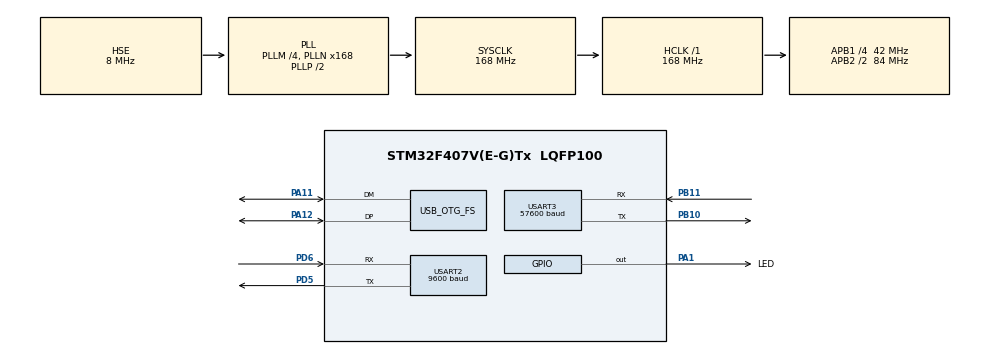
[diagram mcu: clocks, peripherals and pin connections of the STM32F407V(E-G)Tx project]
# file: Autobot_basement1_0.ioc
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Dma.Request0=USART2_RX
Dma.Request1=USART2_TX
Dma.Request2=USART3_RX
Dma.Request3=USART3_TX
Dma.USART2_RX.0.Direction=DMA_PERIPH_TO_MEMORY
Dma.USART2_RX.0.FIFOMode=DMA_FIFOMODE_DISABLE
Dma.USART2_RX.0.Instance=DMA1_Stream5
Dma.USART2_RX.0.MemDataAlignment=DMA_MDATAALIGN_BYTE
Dma.USART2_RX.0.MemInc=DMA_MINC_ENABLE
Dma.USART2_RX.0.Mode=DMA_CIRCULAR
Dma.USART2_RX.0.PeriphDataAlignment=DMA_PDATAALIGN_BYTE
Dma.USART2_RX.0.PeriphInc=DMA_PINC_DISABLE
Dma.USART2_RX.0.Priority=DMA_PRIORITY_LOW
Dma.USART2_TX.1.Direction=DMA_MEMORY_TO_PERIPH
Dma.USART2_TX.1.FIFOMode=DMA_FIFOMODE_DISABLE
Dma.USART2_TX.1.Instance=DMA1_Stream6
Dma.USART2_TX.1.MemDataAlignment=DMA_MDATAALIGN_BYTE
Dma.USART2_TX.1.MemInc=DMA_MINC_ENABLE
Dma.USART2_TX.1.Mode=DMA_NORMAL
Dma.USART2_TX.1.PeriphDataAlignment=DMA_PDATAALIGN_BYTE
Dma.USART2_TX.1.PeriphInc=DMA_PINC_DISABLE
Dma.USART2_TX.1.Priority=DMA_PRIORITY_LOW
Dma.USART3_RX.2.Direction=DMA_PERIPH_TO_MEMORY
Dma.USART3_RX.2.FIFOMode=DMA_FIFOMODE_DISABLE
Dma.USART3_RX.2.Instance=DMA1_Stream1
Dma.USART3_RX.2.MemDataAlignment=DMA_MDATAALIGN_BYTE
Dma.USART3_RX.2.MemInc=DMA_MINC_ENABLE
Dma.USART3_RX.2.Mode=DMA_CIRCULAR
Dma.USART3_RX.2.PeriphDataAlignment=DMA_PDATAALIGN_BYTE
Dma.USART3_RX.2.PeriphInc=DMA_PINC_DISABLE
Dma.USART3_RX.2.Priority=DMA_PRIORITY_LOW
Dma.USART3_TX.3.Direction=DMA_MEMORY_TO_PERIPH
Dma.USART3_TX.3.FIFOMode=DMA_FIFOMODE_DISABLE
Dma.USART3_TX.3.Instance=DMA1_Stream3
Dma.USART3_TX.3.MemDataAlignment=DMA_MDATAALIGN_BYTE
Dma.USART3_TX.3.MemInc=DMA_MINC_ENABLE
Dma.USART3_TX.3.Mode=DMA_NORMAL
Dma.USART3_TX.3.PeriphDataAlignment=DMA_PDATAALIGN_BYTE
Dma.USART3_TX.3.PeriphInc=DMA_PINC_DISABLE
Dma.USART3_TX.3.Priority=DMA_PRIORITY_LOW
FREERTOS.Tasks01=defaultTask,0,128,StartDefaultTask,Default,NULL,Dynamic,NULL,NULL
Mcu.Family=STM32F4
Mcu.Name=STM32F407V(E-G)Tx
Mcu.Package=LQFP100
NVIC.DMA1_Stream1_IRQn=true\:5\:0\:false\:false\:true\:true\:false\:true
NVIC.DMA1_Stream3_IRQn=true\:5\:0\:false\:false\:true\:true\:false\:true
NVIC.DMA1_Stream5_IRQn=true\:5\:0\:false\:false\:true\:true\:false\:true
NVIC.DMA1_Stream6_IRQn=true\:5\:0\:false\:false\:true\:true\:false\:true
NVIC.OTG_FS_IRQn=true\:5\:0\:false\:false\:true\:true\:false\:true
NVIC.PriorityGroup=NVIC_PRIORITYGROUP_4
NVIC.TIM8_TRG_COM_TIM14_IRQn=true\:0\:0\:false\:false\:true\:false\:false\:true
NVIC.TimeBase=TIM8_TRG_COM_TIM14_IRQn
NVIC.TimeBaseIP=TIM14
NVIC.USART2_IRQn=true\:5\:0\:false\:false\:true\:true\:true\:true
NVIC.USART3_IRQn=true\:5\:0\:false\:false\:true\:true\:true\:true
PA1.GPIO_Label=LED
PA1.Signal=GPIO_Output
PA11.Mode=Device_Only
PA11.Signal=USB_OTG_FS_DM
PA12.Mode=Device_Only
PA12.Signal=USB_OTG_FS_DP
PA13.Mode=Serial_Wire
PA13.Signal=SYS_JTMS-SWDIO
PA14.Mode=Serial_Wire
PA14.Signal=SYS_JTCK-SWCLK
PB10.Mode=Asynchronous
PB10.Signal=USART3_TX
PB11.Mode=Asynchronous
PB11.Signal=USART3_RX
PD5.Mode=Asynchronous
PD5.Signal=USART2_TX
PD6.Mode=Asynchronous
PD6.Signal=USART2_RX
PH0-OSC_IN.Mode=HSE-External-Oscillator
PH0-OSC_IN.Signal=RCC_OSC_IN
PH1-OSC_OUT.Mode=HSE-External-Oscillator
PH1-OSC_OUT.Signal=RCC_OSC_OUT
ProjectManager.HeapSize=0x200
ProjectManager.StackSize=0x400
ProjectManager.TargetToolchain=SW4STM32
RCC.48MHZClocksFreq_Value=48000000
RCC.AHBFreq_Value=168000000
RCC.APB1CLKDivider=RCC_HCLK_DIV4
RCC.APB1Freq_Value=42000000
RCC.APB1TimFreq_Value=84000000
RCC.APB2CLKDivider=RCC_HCLK_DIV2
RCC.APB2Freq_Value=84000000
RCC.APB2TimFreq_Value=168000000
RCC.CortexFreq_Value=168000000
RCC.HCLKFreq_Value=168000000
RCC.HSE_VALUE=8000000
RCC.HSI_VALUE=16000000
RCC.LSE_VALUE=32768
RCC.PLLM=4
RCC.PLLN=168
RCC.PLLQ=7
RCC.SYSCLKFreq_VALUE=168000000
RCC.SYSCLKSource=RCC_SYSCLKSOURCE_PLLCLK
RCC.VCOOutputFreq_Value=336000000
USART2.BaudRate=9600
USART2.VirtualMode=VM_ASYNC
USART3.BaudRate=57600
USART3.VirtualMode=VM_ASYNC
USB_DEVICE.CLASS_NAME_FS=CDC
USB_DEVICE.VirtualMode-CDC_FS=Cdc
USB_DEVICE.VirtualModeFS=Cdc_FS
USB_OTG_FS.VirtualMode=Device_Only
VP_FREERTOS_VS_CMSIS_V1.Mode=CMSIS_V1
VP_SYS_VS_tim14.Mode=TIM14
VP_USB_DEVICE_VS_USB_DEVICE_CDC_FS.Mode=CDC_FS
board=custom

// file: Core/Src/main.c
/* USER CODE BEGIN Header */
/**
  ******************************************************************************
  * @file           : main.c
  * @brief          : Main program body
  ******************************************************************************
  * @attention
  *
  * <h2><center>&copy; Copyright (c) 2021 STMicroelectronics.
  * All rights reserved.</center></h2>
  *
  * This software component is licensed by ST under Ultimate Liberty license
  * SLA0044, the "License"; You may not use this file except in compliance with
  * the License. You may obtain a copy of the License at:
  *                             www.st.com/SLA0044
  *
  ******************************************************************************
  */
/* USER CODE END Header */
#include "main.h"
#include "cmsis_os.h"
#include "usb_device.h"

/* USER CODE BEGIN Includes */

#include "macro.h"

/* USER CODE END Includes */

UART_HandleTypeDef huart2;
UART_HandleTypeDef huart3;
DMA_HandleTypeDef hdma_usart2_rx;
DMA_HandleTypeDef hdma_usart2_tx;
DMA_HandleTypeDef hdma_usart3_rx;
DMA_HandleTypeDef hdma_usart3_tx;

osThreadId defaultTaskHandle;

void SystemClock_Config(void);
static void MX_GPIO_Init(void);
static void MX_DMA_Init(void);
static void MX_USART2_UART_Init(void);
static void MX_USART3_UART_Init(void);
void StartDefaultTask(void const * argument);

int main(void)
{

  /* MCU Configuration--------------------------------------------------------*/

  /* Reset of all peripherals, Initializes the Flash interface and the Systick. */
  HAL_Init();

  /* Configure the system clock */
  SystemClock_Config();

  /* Initialize all configured peripherals */
  MX_GPIO_Init();
  MX_DMA_Init();
  MX_USART2_UART_Init();
  MX_USART3_UART_Init();
  /* USER CODE BEGIN 2 */

  ParamsInit();

  /* USER CODE END 2 */

  /* Create the thread(s) */
  /* definition and creation of defaultTask */
  osThreadDef(defaultTask, StartDefaultTask, osPriorityNormal, 0, 128);
  defaultTaskHandle = osThreadCreate(osThread(defaultTask), NULL);

  /* Start scheduler */
  osKernelStart();

  /* We should never get here as control is now taken by the scheduler */
  /* Infinite loop */
	while (1) {

	}
}

void SystemClock_Config(void)
{
  RCC_OscInitTypeDef RCC_OscInitStruct = {0};
  RCC_ClkInitTypeDef RCC_ClkInitStruct = {0};

  /** Configure the main internal regulator output voltage
  */
  __HAL_RCC_PWR_CLK_ENABLE();
  __HAL_PWR_VOLTAGESCALING_CONFIG(PWR_REGULATOR_VOLTAGE_SCALE1);
  /** Initializes the RCC Oscillators according to the specified parameters
  * in the RCC_OscInitTypeDef structure.
  */
  RCC_OscInitStruct.OscillatorType = RCC_OSCILLATORTYPE_HSE;
  RCC_OscInitStruct.HSEState = RCC_HSE_ON;
  RCC_OscInitStruct.PLL.PLLState = RCC_PLL_ON;
  RCC_OscInitStruct.PLL.PLLSource = RCC_PLLSOURCE_HSE;
  RCC_OscInitStruct.PLL.PLLM = 4;
  RCC_OscInitStruct.PLL.PLLN = 168;
  RCC_OscInitStruct.PLL.PLLP = RCC_PLLP_DIV2;
  RCC_OscInitStruct.PLL.PLLQ = 7;
  if (HAL_RCC_OscConfig(&RCC_OscInitStruct) != HAL_OK)
  {
    Error_Handler();
  }
  /** Initializes the CPU, AHB and APB buses clocks
  */
  RCC_ClkInitStruct.ClockType = RCC_CLOCKTYPE_HCLK|RCC_CLOCKTYPE_SYSCLK
                              |RCC_CLOCKTYPE_PCLK1|RCC_CLOCKTYPE_PCLK2;
  RCC_ClkInitStruct.SYSCLKSource = RCC_SYSCLKSOURCE_PLLCLK;
  RCC_ClkInitStruct.AHBCLKDivider = RCC_SYSCLK_DIV1;
  RCC_ClkInitStruct.APB1CLKDivider = RCC_HCLK_DIV4;
  RCC_ClkInitStruct.APB2CLKDivider = RCC_HCLK_DIV2;

  if (HAL_RCC_ClockConfig(&RCC_ClkInitStruct, FLASH_LATENCY_5) != HAL_OK)
  {
    Error_Handler();
  }
}

static void MX_USART2_UART_Init(void)
{

  huart2.Instance = USART2;
  huart2.Init.BaudRate = 9600;
  huart2.Init.WordLength = UART_WORDLENGTH_8B;
  huart2.Init.StopBits = UART_STOPBITS_1;
  huart2.Init.Parity = UART_PARITY_NONE;
  huart2.Init.Mode = UART_MODE_TX_RX;
  huart2.Init.HwFlowCtl = UART_HWCONTROL_NONE;
  huart2.Init.OverSampling = UART_OVERSAMPLING_16;
  if (HAL_UART_Init(&huart2) != HAL_OK)
  {
    Error_Handler();
  }

}

static void MX_USART3_UART_Init(void)
{

  huart3.Instance = USART3;
  huart3.Init.BaudRate = 57600;
  huart3.Init.WordLength = UART_WORDLENGTH_8B;
  huart3.Init.StopBits = UART_STOPBITS_1;
  huart3.Init.Parity = UART_PARITY_NONE;
  huart3.Init.Mode = UART_MODE_TX_RX;
  huart3.Init.HwFlowCtl = UART_HWCONTROL_NONE;
  huart3.Init.OverSampling = UART_OVERSAMPLING_16;
  if (HAL_UART_Init(&huart3) != HAL_OK)
  {
    Error_Handler();
  }

}

static void MX_DMA_Init(void)
{

  /* DMA controller clock enable */
  __HAL_RCC_DMA1_CLK_ENABLE();

  /* DMA interrupt init */
  /* DMA1_Stream1_IRQn interrupt configuration */
  HAL_NVIC_SetPriority(DMA1_Stream1_IRQn, 5, 0);
  HAL_NVIC_EnableIRQ(DMA1_Stream1_IRQn);
  /* DMA1_Stream3_IRQn interrupt configuration */
  HAL_NVIC_SetPriority(DMA1_Stream3_IRQn, 5, 0);
  HAL_NVIC_EnableIRQ(DMA1_Stream3_IRQn);
  /* DMA1_Stream5_IRQn interrupt configuration */
  HAL_NVIC_SetPriority(DMA1_Stream5_IRQn, 5, 0);
  HAL_NVIC_EnableIRQ(DMA1_Stream5_IRQn);
  /* DMA1_Stream6_IRQn interrupt configuration */
  HAL_NVIC_SetPriority(DMA1_Stream6_IRQn, 5, 0);
  HAL_NVIC_EnableIRQ(DMA1_Stream6_IRQn);

}

static void MX_GPIO_Init(void)
{
  GPIO_InitTypeDef GPIO_InitStruct = {0};

  /* GPIO Ports Clock Enable */
  __HAL_RCC_GPIOH_CLK_ENABLE();
  __HAL_RCC_GPIOA_CLK_ENABLE();
  __HAL_RCC_GPIOB_CLK_ENABLE();
  __HAL_RCC_GPIOD_CLK_ENABLE();

  /*Configure GPIO pin Output Level */
  HAL_GPIO_WritePin(LED_GPIO_Port, LED_Pin, GPIO_PIN_RESET);

  /*Configure GPIO pin : LED_Pin */
  GPIO_InitStruct.Pin = LED_Pin;
  GPIO_InitStruct.Mode = GPIO_MODE_OUTPUT_PP;
  GPIO_InitStruct.Pull = GPIO_NOPULL;
  GPIO_InitStruct.Speed = GPIO_SPEED_FREQ_LOW;
  HAL_GPIO_Init(LED_GPIO_Port, &GPIO_InitStruct);

}

void StartDefaultTask(void const * argument)
{
  /* init code for USB_DEVICE */
  MX_USB_DEVICE_Init();
  /* USER CODE BEGIN 5 */

	setup();

	/* Infinite loop */
	for (;;) {
//        HAL_GPIO_TogglePin(LED_GPIO_Port, LED_Pin);
//        osDelay(100);

		loop();

		osDelay(50);

	}
  /* USER CODE END 5 */
}

 /**
  * @brief  Period elapsed callback in non blocking mode
  * @note   This function is called  when TIM14 interrupt took place, inside
  * HAL_TIM_IRQHandler(). It makes a direct call to HAL_IncTick() to increment
  * a global variable "uwTick" used as application time base.
  * @param  htim : TIM handle
  * @retval None
  */
void HAL_TIM_PeriodElapsedCallback(TIM_HandleTypeDef *htim)
{
  if (htim->Instance == TIM14) {
    HAL_IncTick();
  }
}

void Error_Handler(void)
{
	__disable_irq();
	while (1) {
	}
}

/************************ (C) COPYRIGHT STMicroelectronics *****END OF FILE****/
